# ATSAMD20E16BU device description
Architecture: CORTEX-M0PLUS; Family: SAMD; Series: SAMD20
Registers are 8-bit, read-write, reset 0x0 unless marked. A register's access mark holds for its fields unless they carry their own. Offsets are from the block's base; [hi:lo] are bit positions; {n}, {i} and the like mark numbered series; 'fields as' and 'values as' point back to an identical list.

## EVSYS — Event System Interface
Instances: EVSYS 0x42000400
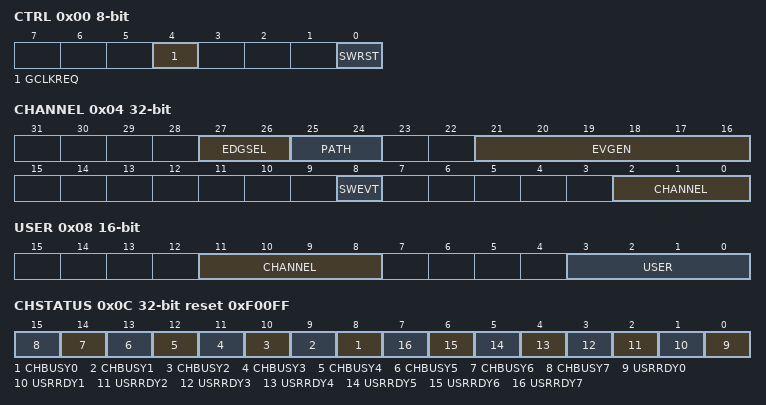
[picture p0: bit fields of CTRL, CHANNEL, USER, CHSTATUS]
0x00 CTRL wo — Control
  [4] GCLKREQ — Generic Clock Requests
  [0] SWRST — Software Reset
0x04 CHANNEL 32-bit
  [27:26] EDGSEL — Edge Detection Selection
    0=NO_EVT_OUTPUT (No event output when using the resynchronized or synchronous path); 1=RISING_EDGE (Event detection only on the rising edge of the signal from the event generator when using the resynchronized or synchronous path); 2=FALLING_EDGE (Event detection only on the falling edge of the signal from the event generator when using the resynchronized or synchronous path); 3=BOTH_EDGES (Event detection on rising and falling edges of the signal from the event generator when using the resynchronized or synchronous path)
  [25:24] PATH — Path Selection
    0=SYNCHRONOUS (Synchronous path); 1=RESYNCHRONIZED (Resynchronized path); 2=ASYNCHRONOUS (Asynchronous path)
  [21:16] EVGEN — Event Generator Selection
  [8] SWEVT — Software Event
  [2:0] CHANNEL — Channel Selection
0x08 USER 16-bit — User Multiplexer
  [11:8] CHANNEL — Channel Event Selection
    0=No Channel Output Selected
  [3:0] USER — User Multiplexer Selection
0x0C CHSTATUS 32-bit ro reset 0xF00FF — Channel Status
  [n+8] CHBUSY{n} (n=0..7) — Channel {n} Busy
  [n] USRRDY{n} (n=0..7) — Channel {n} User Ready
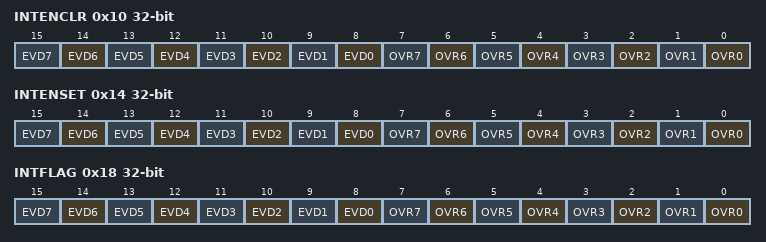
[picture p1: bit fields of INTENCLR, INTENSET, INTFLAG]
0x10 INTENCLR 32-bit (atomic clear) — Interrupt Enable Clear
  [n+8] EVD{n} (n=0..7) — Channel {n} Event Detection Interrupt Enable
  [n] OVR{n} (n=0..7) — Channel {n} Overrun Interrupt Enable
0x14 INTENSET 32-bit (atomic set) — Interrupt Enable Set
  fields as INTENCLR
0x18 INTFLAG 32-bit (atomic clear) — Interrupt Flag Status and Clear
  [n+8] EVD{n} (n=0..7) — Channel {n} Event Detection
  [n] OVR{n} (n=0..7) — Channel {n} Overrun

## GCLK — Generic Clock Generator
Instances: GCLK 0x40000C00
0x00 CTRL (WSYNC) — Control
  [0] SWRST — Software Reset
0x01 STATUS ro
  [7] SYNCBUSY — Synchronization Busy Status
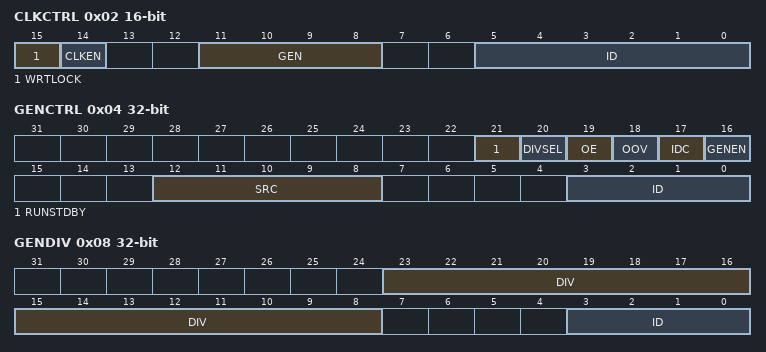
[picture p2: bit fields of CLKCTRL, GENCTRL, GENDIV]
0x02 CLKCTRL 16-bit — Generic Clock Control
  [15] WRTLOCK — Write Lock
  [14] CLKEN — Clock Enable
  [11:8] GEN — Generic Clock Generator
    {v}=GCLK{v} (Generic clock generator {v}) (v=0..7)
  [5:0] ID — Generic Clock Selection ID
    0=DFLL48M (DFLL48M Reference); 1=WDT; 2=RTC; 3=EIC; {v}=EVSYS_CHANNEL_{v-4} (v=4..11); 12=SERCOMX_SLOW; {v}=SERCOM{v-13}_CORE (v=13..18); 19=TC0_TC1; 20=TC2_TC3; 21=TC4_TC5; 22=TC6_TC7; 23=ADC; 24=AC_DIG; 25=AC_ANA; 26=DAC
0x04 GENCTRL 32-bit (WSYNC) — Generic Clock Generator Control
  [21] RUNSTDBY — Run in Standby
  [20] DIVSEL — Divide Selection
    0=DIV1 (Divide input directly by divider factor); 1=DIV2 (Divide input by 2^(divider factor+ 1))
  [19] OE — Output Enable
  [18] OOV — Output Off Value
  [17] IDC — Improve Duty Cycle
  [16] GENEN — Generic Clock Generator Enable
  [12:8] SRC — Source Select
    0=XOSC (XOSC oscillator output); 1=GCLKIN (Generator input pad); 2=GCLKGEN1 (Generic clock generator 1 output); 3=OSCULP32K (OSCULP32K oscillator output); 4=OSC32K (OSC32K oscillator output); 5=XOSC32K (XOSC32K oscillator output); 6=OSC8M (OSC8M oscillator output); 7=DFLL48M (DFLL48M output)
  [3:0] ID — Generic Clock Generator Selection
    {v}=GCLK{v} (Generic clock generator {v}) (v=0..7)
0x08 GENDIV 32-bit — Generic Clock Generator Division
  [23:8] DIV — Division Factor
  [3:0] ID — Generic Clock Generator Selection
    {v}=GCLK{v} (Generic clock generator {v}) (v=0..7)

## NVMCTRL — Non-Volatile Memory Controller
Instances: NVMCTRL 0x41004000
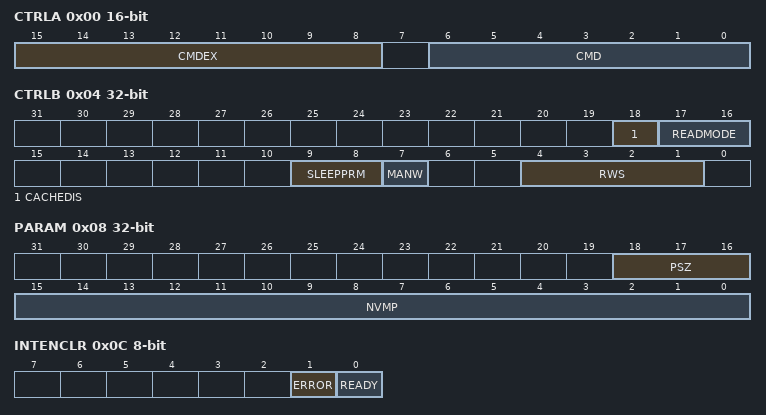
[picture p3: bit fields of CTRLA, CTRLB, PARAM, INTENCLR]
0x00 CTRLA 16-bit — Control A
  [15:8] CMDEX — Command Execution
    165=KEY (Execution Key)
  [6:0] CMD — Command
    2=ER (Erase Row - Erases the row addressed by the ADDR register.); 4=WP (Write Page - Writes the contents of the page buffer to the page addressed by the ADDR register.); 5=EAR (Erase Auxiliary Row - Erases the auxiliary row addressed by the ADDR register. This command can be given only when the security bit is not set and only to the user configuration row.); 6=WAP (Write Auxiliary Page - Writes the contents of the page buffer to the page addressed by the ADDR register. This command can be given only when the security bit is not set and only to the user configuration row.); 10=SF (Security Flow Command); 15=WL (Write lockbits); 64=LR (Lock Region - Locks the region containing the address location in the ADDR register.); 65=UR (Unlock Region - Unlocks the region containing the address location in the ADDR register.); 66=SPRM (Sets the power reduction mode.); 67=CPRM (Clears the power reduction mode.); 68=PBC (Page Buffer Clear - Clears the page buffer.); 69=SSB (Set Security Bit - Sets the security bit by writing 0x00 to the first byte in the lockbit row.); 70=INVALL (Invalidate all cache lines.)
0x04 CTRLB 32-bit — Control B
  [18] CACHEDIS — Cache Disable
  [17:16] READMODE — NVMCTRL Read Mode
    0=NO_MISS_PENALTY (The NVM Controller (cache system) does not insert wait states on a cache miss. Gives the best system performance.); 1=LOW_POWER (Reduces power consumption of the cache system, but inserts a wait state each time there is a cache miss. This mode may not be relevant if CPU performance is required, as the application will be stalled and may lead to increase run time.); 2=DETERMINISTIC (The cache system ensures that a cache hit or miss takes the same amount of time, determined by the number of programmed flash wait states. This mode can be used for real-time applications that require deterministic execution timings.)
  [9:8] SLEEPPRM — Power Reduction Mode during Sleep
    0=WAKEONACCESS (NVM block enters low-power mode when entering sleep.NVM block exits low-power mode upon first access.); 1=WAKEUPINSTANT (NVM block enters low-power mode when entering sleep.NVM block exits low-power mode when exiting sleep.); 3=DISABLED (Auto power reduction disabled.)
  [7] MANW — Manual Write
  [4:1] RWS — NVM Read Wait States
    0=SINGLE (Single Auto Wait State); 1=HALF (Half Auto Wait State); 2=DUAL (Dual Auto Wait State)
0x08 PARAM 32-bit — NVM Parameter
  [18:16] PSZ — Page Size
    0=8 bytes; 1=16 bytes; 2=32 bytes; 3=64 bytes; 4=128 bytes; 5=256 bytes; 6=512 bytes; 7=1024 bytes
  [15:0] NVMP — NVM Pages
0x0C INTENCLR (atomic clear) — Interrupt Enable Clear
  [1] ERROR — Error Interrupt Enable
  [0] READY — NVM Ready Interrupt Enable
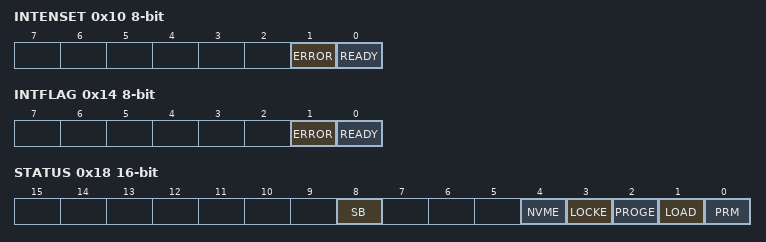
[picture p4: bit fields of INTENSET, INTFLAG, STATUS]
0x10 INTENSET (atomic set) — Interrupt Enable Set
  fields as INTENCLR
0x14 INTFLAG (atomic clear) — Interrupt Flag Status and Clear
  [1] ERROR
  [0] READY — NVM Ready
0x18 STATUS 16-bit
  [8] SB — Security Bit Status
  [4] NVME — NVM Error
  [3] LOCKE — Lock Error Status
  [2] PROGE — Programming Error Status
  [1] LOAD — NVM Page Buffer Active Loading
  [0] PRM — Power Reduction Mode
0x1C ADDR 32-bit — Address
  [21:0] ADDR — NVM Address
0x20 LOCK 16-bit — Lock Section
  [15:0] LOCK — Region Lock Bits

## Notices in the file
Copyright (c) 2019 Microchip Technology Inc.
SPDX-License-Identifier: Apache-2.0
Licensed under the Apache License, Version 2.0 (the "License");
you may not use this file except in compliance with the License.
You may obtain a copy of the License at
http://www.apache.org/licenses/LICENSE-2.0
Unless required by applicable law or agreed to in writing, software
distributed under the License is distributed on an "AS IS" BASIS,
WITHOUT WARRANTIES OR CONDITIONS OF ANY KIND, either express or implied.
See the License for the specific language governing permissions and
limitations under the License.
